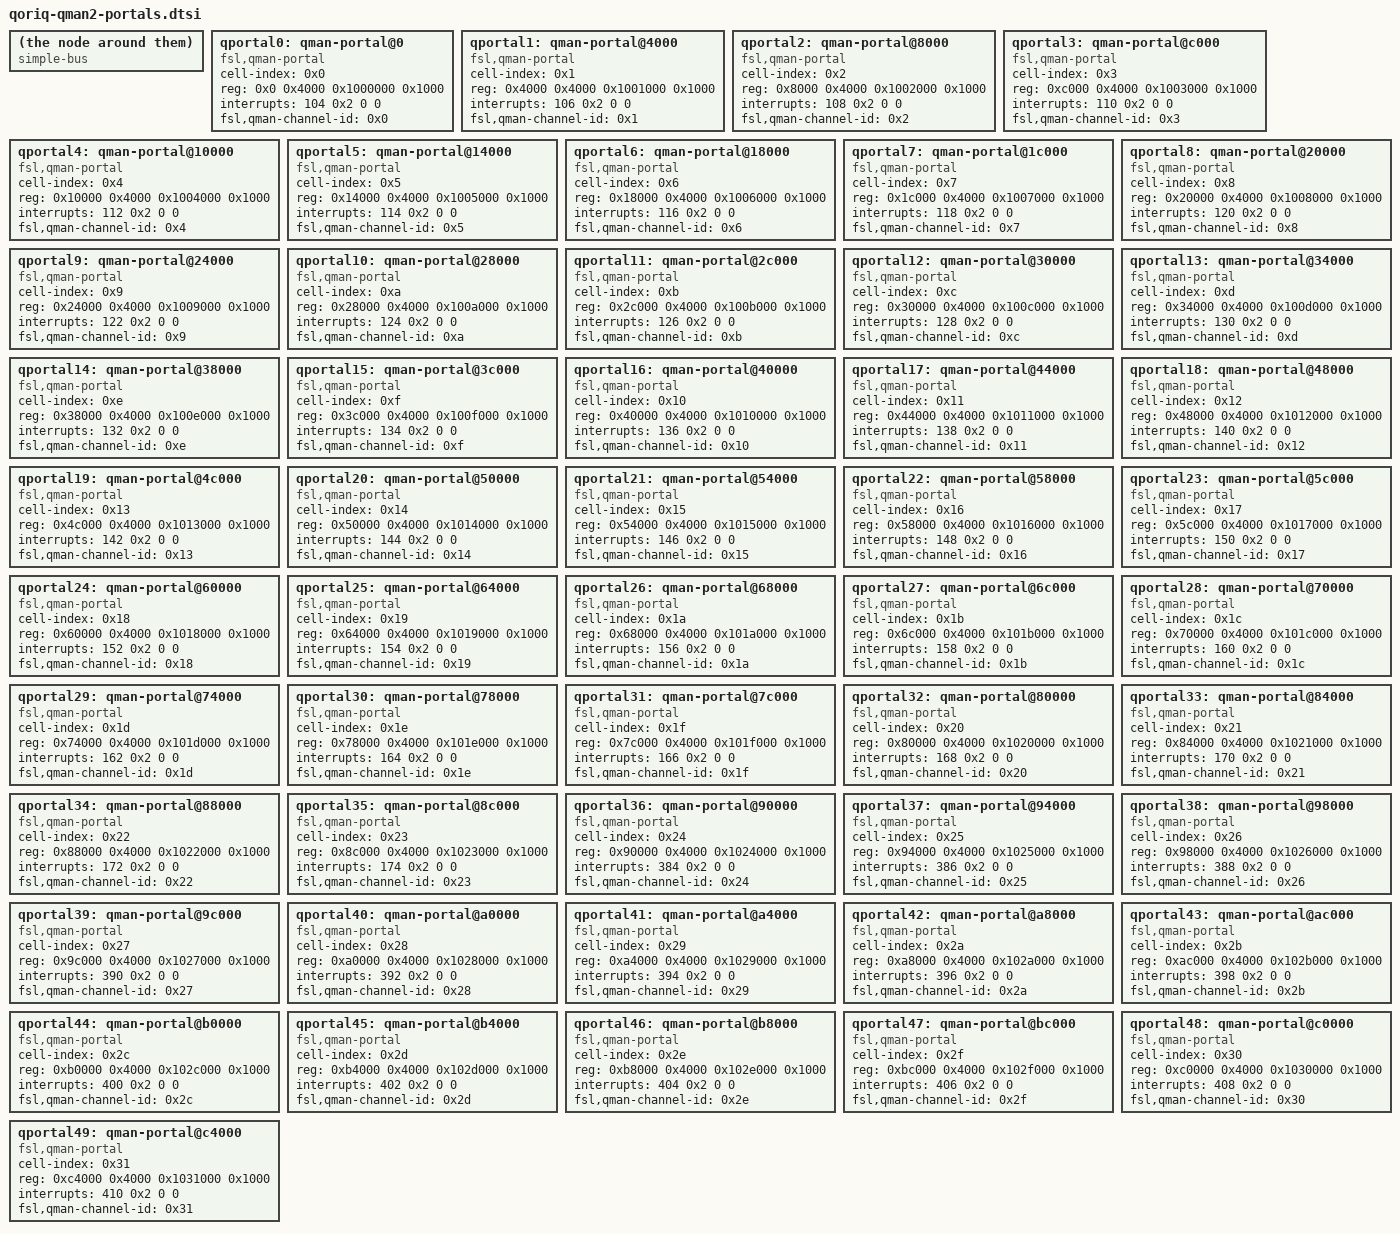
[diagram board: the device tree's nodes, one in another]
/*
 * QorIQ QMan Portal device tree stub for QMan 3.0 with maximum 50 portals.
 *
 * Copyright 2011-2012 Freescale Semiconductor Inc.
 *
 * Redistribution and use in source and binary forms, with or without
 * modification, are permitted provided that the following conditions are met:
 *     * Redistributions of source code must retain the above copyright
 *       notice, this list of conditions and the following disclaimer.
 *     * Redistributions in binary form must reproduce the above copyright
 *       notice, this list of conditions and the following disclaimer in the
 *       documentation and/or other materials provided with the distribution.
 *     * Neither the name of Freescale Semiconductor nor the
 *       names of its contributors may be used to endorse or promote products
 *       derived from this software without specific prior written permission.
 *
 *
 * ALTERNATIVELY, this software may be distributed under the terms of the
 * GNU General Public License ("GPL") as published by the Free Software
 * Foundation, either version 2 of that License or (at your option) any
 * later version.
 *
 * THIS SOFTWARE IS PROVIDED BY Freescale Semiconductor ``AS IS'' AND ANY
 * EXPRESS OR IMPLIED WARRANTIES, INCLUDING, BUT NOT LIMITED TO, THE IMPLIED
 * WARRANTIES OF MERCHANTABILITY AND FITNESS FOR A PARTICULAR PURPOSE ARE
 * DISCLAIMED. IN NO EVENT SHALL Freescale Semiconductor BE LIABLE FOR ANY
 * DIRECT, INDIRECT, INCIDENTAL, SPECIAL, EXEMPLARY, OR CONSEQUENTIAL DAMAGES
 * (INCLUDING, BUT NOT LIMITED TO, PROCUREMENT OF SUBSTITUTE GOODS OR SERVICES;
 * LOSS OF USE, DATA, OR PROFITS; OR BUSINESS INTERRUPTION) HOWEVER CAUSED AND
 * ON ANY THEORY OF LIABILITY, WHETHER IN CONTRACT, STRICT LIABILITY, OR TORT
 * (INCLUDING NEGLIGENCE OR OTHERWISE) ARISING IN ANY WAY OUT OF THE USE OF THIS
 * SOFTWARE, EVEN IF ADVISED OF THE POSSIBILITY OF SUCH DAMAGE.
 */

#address-cells = <0x1>;
#size-cells = <0x1>;
compatible = "simple-bus";
qportal0: qman-portal@0 {
	cell-index = <0x0>;
	compatible = "fsl,qman-portal";
	reg = <0x0 0x4000 0x1000000 0x1000>;
	interrupts = <104 0x2 0 0>;
	fsl,qman-channel-id = <0x0>;
};

qportal1: qman-portal@4000 {
	cell-index = <0x1>;
	compatible = "fsl,qman-portal";
	reg = <0x4000 0x4000 0x1001000 0x1000>;
	interrupts = <106 0x2 0 0>;
	fsl,qman-channel-id = <0x1>;
};

qportal2: qman-portal@8000 {
	cell-index = <0x2>;
	compatible = "fsl,qman-portal";
	reg = <0x8000 0x4000 0x1002000 0x1000>;
	interrupts = <108 0x2 0 0>;
	fsl,qman-channel-id = <0x2>;
};

qportal3: qman-portal@c000 {
	cell-index = <0x3>;
	compatible = "fsl,qman-portal";
	reg = <0xc000 0x4000 0x1003000 0x1000>;
	interrupts = <110 0x2 0 0>;
	fsl,qman-channel-id = <0x3>;
};

qportal4: qman-portal@10000 {
	cell-index = <0x4>;
	compatible = "fsl,qman-portal";
	reg = <0x10000 0x4000 0x1004000 0x1000>;
	interrupts = <112 0x2 0 0>;
	fsl,qman-channel-id = <0x4>;
};

qportal5: qman-portal@14000 {
	cell-index = <0x5>;
	compatible = "fsl,qman-portal";
	reg = <0x14000 0x4000 0x1005000 0x1000>;
	interrupts = <114 0x2 0 0>;
	fsl,qman-channel-id = <0x5>;
};

qportal6: qman-portal@18000 {
	cell-index = <0x6>;
	compatible = "fsl,qman-portal";
	reg = <0x18000 0x4000 0x1006000 0x1000>;
	interrupts = <116 0x2 0 0>;
	fsl,qman-channel-id = <0x6>;
};

qportal7: qman-portal@1c000 {
	cell-index = <0x7>;
	compatible = "fsl,qman-portal";
	reg = <0x1c000 0x4000 0x1007000 0x1000>;
	interrupts = <118 0x2 0 0>;
	fsl,qman-channel-id = <0x7>;
};

qportal8: qman-portal@20000 {
	cell-index = <0x8>;
	compatible = "fsl,qman-portal";
	reg = <0x20000 0x4000 0x1008000 0x1000>;
	interrupts = <120 0x2 0 0>;
	fsl,qman-channel-id = <0x8>;
};

qportal9: qman-portal@24000 {
	cell-index = <0x9>;
	compatible = "fsl,qman-portal";
	reg = <0x24000 0x4000 0x1009000 0x1000>;
	interrupts = <122 0x2 0 0>;
	fsl,qman-channel-id = <0x9>;
};

qportal10: qman-portal@28000 {
	cell-index = <0xa>;
	compatible = "fsl,qman-portal";
	reg = <0x28000 0x4000 0x100a000 0x1000>;
	interrupts = <124 0x2 0 0>;
	fsl,qman-channel-id = <0xa>;
};

qportal11: qman-portal@2c000 {
	cell-index = <0xb>;
	compatible = "fsl,qman-portal";
	reg = <0x2c000 0x4000 0x100b000 0x1000>;
	interrupts = <126 0x2 0 0>;
	fsl,qman-channel-id = <0xb>;
};

qportal12: qman-portal@30000 {
	cell-index = <0xc>;
	compatible = "fsl,qman-portal";
	reg = <0x30000 0x4000 0x100c000 0x1000>;
	interrupts = <128 0x2 0 0>;
	fsl,qman-channel-id = <0xc>;
};

qportal13: qman-portal@34000 {
	cell-index = <0xd>;
	compatible = "fsl,qman-portal";
	reg = <0x34000 0x4000 0x100d000 0x1000>;
	interrupts = <130 0x2 0 0>;
	fsl,qman-channel-id = <0xd>;
};

qportal14: qman-portal@38000 {
	cell-index = <0xe>;
	compatible = "fsl,qman-portal";
	reg = <0x38000 0x4000 0x100e000 0x1000>;
	interrupts = <132 0x2 0 0>;
	fsl,qman-channel-id = <0xe>;
};

qportal15: qman-portal@3c000 {
	cell-index = <0xf>;
	compatible = "fsl,qman-portal";
	reg = <0x3c000 0x4000 0x100f000 0x1000>;
	interrupts = <134 0x2 0 0>;
	fsl,qman-channel-id = <0xf>;
};

qportal16: qman-portal@40000 {
	cell-index = <0x10>;
	compatible = "fsl,qman-portal";
	reg = <0x40000 0x4000 0x1010000 0x1000>;
	interrupts = <136 0x2 0 0>;
	fsl,qman-channel-id = <0x10>;
};

qportal17: qman-portal@44000 {
	cell-index = <0x11>;
	compatible = "fsl,qman-portal";
	reg = <0x44000 0x4000 0x1011000 0x1000>;
	interrupts = <138 0x2 0 0>;
	fsl,qman-channel-id = <0x11>;
};

qportal18: qman-portal@48000 {
	cell-index = <0x12>;
	compatible = "fsl,qman-portal";
	reg = <0x48000 0x4000 0x1012000 0x1000>;
	interrupts = <140 0x2 0 0>;
	fsl,qman-channel-id = <0x12>;
};

qportal19: qman-portal@4c000 {
	cell-index = <0x13>;
	compatible = "fsl,qman-portal";
	reg = <0x4c000 0x4000 0x1013000 0x1000>;
	interrupts = <142 0x2 0 0>;
	fsl,qman-channel-id = <0x13>;
};

qportal20: qman-portal@50000 {
	cell-index = <0x14>;
	compatible = "fsl,qman-portal";
	reg = <0x50000 0x4000 0x1014000 0x1000>;
	interrupts = <144 0x2 0 0>;
	fsl,qman-channel-id = <0x14>;
};

qportal21: qman-portal@54000 {
	cell-index = <0x15>;
	compatible = "fsl,qman-portal";
	reg = <0x54000 0x4000 0x1015000 0x1000>;
	interrupts = <146 0x2 0 0>;
	fsl,qman-channel-id = <0x15>;
};

qportal22: qman-portal@58000 {
	cell-index = <0x16>;
	compatible = "fsl,qman-portal";
	reg = <0x58000 0x4000 0x1016000 0x1000>;
	interrupts = <148 0x2 0 0>;
	fsl,qman-channel-id = <0x16>;
};

qportal23: qman-portal@5c000 {
	cell-index = <0x17>;
	compatible = "fsl,qman-portal";
	reg = <0x5c000 0x4000 0x1017000 0x1000>;
	interrupts = <150 0x2 0 0>;
	fsl,qman-channel-id = <0x17>;
};

qportal24: qman-portal@60000 {
	cell-index = <0x18>;
	compatible = "fsl,qman-portal";
	reg = <0x60000 0x4000 0x1018000 0x1000>;
	interrupts = <152 0x2 0 0>;
	fsl,qman-channel-id = <0x18>;
};

qportal25: qman-portal@64000 {
	cell-index = <0x19>;
	compatible = "fsl,qman-portal";
	reg = <0x64000 0x4000 0x1019000 0x1000>;
	interrupts = <154 0x2 0 0>;
	fsl,qman-channel-id = <0x19>;
};

qportal26: qman-portal@68000 {
	cell-index = <0x1a>;
	compatible = "fsl,qman-portal";
	reg = <0x68000 0x4000 0x101a000 0x1000>;
	interrupts = <156 0x2 0 0>;
	fsl,qman-channel-id = <0x1a>;
};

qportal27: qman-portal@6c000 {
	cell-index = <0x1b>;
	compatible = "fsl,qman-portal";
	reg = <0x6c000 0x4000 0x101b000 0x1000>;
	interrupts = <158 0x2 0 0>;
	fsl,qman-channel-id = <0x1b>;
};

qportal28: qman-portal@70000 {
	cell-index = <0x1c>;
	compatible = "fsl,qman-portal";
	reg = <0x70000 0x4000 0x101c000 0x1000>;
	interrupts = <160 0x2 0 0>;
	fsl,qman-channel-id = <0x1c>;
};

qportal29: qman-portal@74000 {
	cell-index = <0x1d>;
	compatible = "fsl,qman-portal";
	reg = <0x74000 0x4000 0x101d000 0x1000>;
	interrupts = <162 0x2 0 0>;
	fsl,qman-channel-id = <0x1d>;
};

qportal30: qman-portal@78000 {
	cell-index = <0x1e>;
	compatible = "fsl,qman-portal";
	reg = <0x78000 0x4000 0x101e000 0x1000>;
	interrupts = <164 0x2 0 0>;
	fsl,qman-channel-id = <0x1e>;
};

qportal31: qman-portal@7c000 {
	cell-index = <0x1f>;
	compatible = "fsl,qman-portal";
	reg = <0x7c000 0x4000 0x101f000 0x1000>;
	interrupts = <166 0x2 0 0>;
	fsl,qman-channel-id = <0x1f>;
};

qportal32: qman-portal@80000 {
	cell-index = <0x20>;
	compatible = "fsl,qman-portal";
	reg = <0x80000 0x4000 0x1020000 0x1000>;
	interrupts = <168 0x2 0 0>;
	fsl,qman-channel-id = <0x20>;
};

qportal33: qman-portal@84000 {
	cell-index = <0x21>;
	compatible = "fsl,qman-portal";
	reg = <0x84000 0x4000 0x1021000 0x1000>;
	interrupts = <170 0x2 0 0>;
	fsl,qman-channel-id = <0x21>;
};

qportal34: qman-portal@88000 {
	cell-index = <0x22>;
	compatible = "fsl,qman-portal";
	reg = <0x88000 0x4000 0x1022000 0x1000>;
	interrupts = <172 0x2 0 0>;
	fsl,qman-channel-id = <0x22>;
};

qportal35: qman-portal@8c000 {
	cell-index = <0x23>;
	compatible = "fsl,qman-portal";
	reg = <0x8c000 0x4000 0x1023000 0x1000>;
	interrupts = <174 0x2 0 0>;
	fsl,qman-channel-id = <0x23>;
};

qportal36: qman-portal@90000 {
	cell-index = <0x24>;
	compatible = "fsl,qman-portal";
	reg = <0x90000 0x4000 0x1024000 0x1000>;
	interrupts = <384 0x2 0 0>;
	fsl,qman-channel-id = <0x24>;
};

qportal37: qman-portal@94000 {
	cell-index = <0x25>;
	compatible = "fsl,qman-portal";
	reg = <0x94000 0x4000 0x1025000 0x1000>;
	interrupts = <386 0x2 0 0>;
	fsl,qman-channel-id = <0x25>;
};

qportal38: qman-portal@98000 {
	cell-index = <0x26>;
	compatible = "fsl,qman-portal";
	reg = <0x98000 0x4000 0x1026000 0x1000>;
	interrupts = <388 0x2 0 0>;
	fsl,qman-channel-id = <0x26>;
};

qportal39: qman-portal@9c000 {
	cell-index = <0x27>;
	compatible = "fsl,qman-portal";
	reg = <0x9c000 0x4000 0x1027000 0x1000>;
	interrupts = <390 0x2 0 0>;
	fsl,qman-channel-id = <0x27>;
};

qportal40: qman-portal@a0000 {
	cell-index = <0x28>;
	compatible = "fsl,qman-portal";
	reg = <0xa0000 0x4000 0x1028000 0x1000>;
	interrupts = <392 0x2 0 0>;
	fsl,qman-channel-id = <0x28>;
};

qportal41: qman-portal@a4000 {
	cell-index = <0x29>;
	compatible = "fsl,qman-portal";
	reg = <0xa4000 0x4000 0x1029000 0x1000>;
	interrupts = <394 0x2 0 0>;
	fsl,qman-channel-id = <0x29>;
};

qportal42: qman-portal@a8000 {
	cell-index = <0x2a>;
	compatible = "fsl,qman-portal";
	reg = <0xa8000 0x4000 0x102a000 0x1000>;
	interrupts = <396 0x2 0 0>;
	fsl,qman-channel-id = <0x2a>;
};

qportal43: qman-portal@ac000 {
	cell-index = <0x2b>;
	compatible = "fsl,qman-portal";
	reg = <0xac000 0x4000 0x102b000 0x1000>;
	interrupts = <398 0x2 0 0>;
	fsl,qman-channel-id = <0x2b>;
};

qportal44: qman-portal@b0000 {
	cell-index = <0x2c>;
	compatible = "fsl,qman-portal";
	reg = <0xb0000 0x4000 0x102c000 0x1000>;
	interrupts = <400 0x2 0 0>;
	fsl,qman-channel-id = <0x2c>;
};

qportal45: qman-portal@b4000 {
	cell-index = <0x2d>;
	compatible = "fsl,qman-portal";
	reg = <0xb4000 0x4000 0x102d000 0x1000>;
	interrupts = <402 0x2 0 0>;
	fsl,qman-channel-id = <0x2d>;
};

qportal46: qman-portal@b8000 {
	cell-index = <0x2e>;
	compatible = "fsl,qman-portal";
	reg = <0xb8000 0x4000 0x102e000 0x1000>;
	interrupts = <404 0x2 0 0>;
	fsl,qman-channel-id = <0x2e>;
};

qportal47: qman-portal@bc000 {
	cell-index = <0x2f>;
	compatible = "fsl,qman-portal";
	reg = <0xbc000 0x4000 0x102f000 0x1000>;
	interrupts = <406 0x2 0 0>;
	fsl,qman-channel-id = <0x2f>;
};

qportal48: qman-portal@c0000 {
	cell-index = <0x30>;
	compatible = "fsl,qman-portal";
	reg = <0xc0000 0x4000 0x1030000 0x1000>;
	interrupts = <408 0x2 0 0>;
	fsl,qman-channel-id = <0x30>;
};

qportal49: qman-portal@c4000 {
	cell-index = <0x31>;
	compatible = "fsl,qman-portal";
	reg = <0xc4000 0x4000 0x1031000 0x1000>;
	interrupts = <410 0x2 0 0>;
	fsl,qman-channel-id = <0x31>;
};
